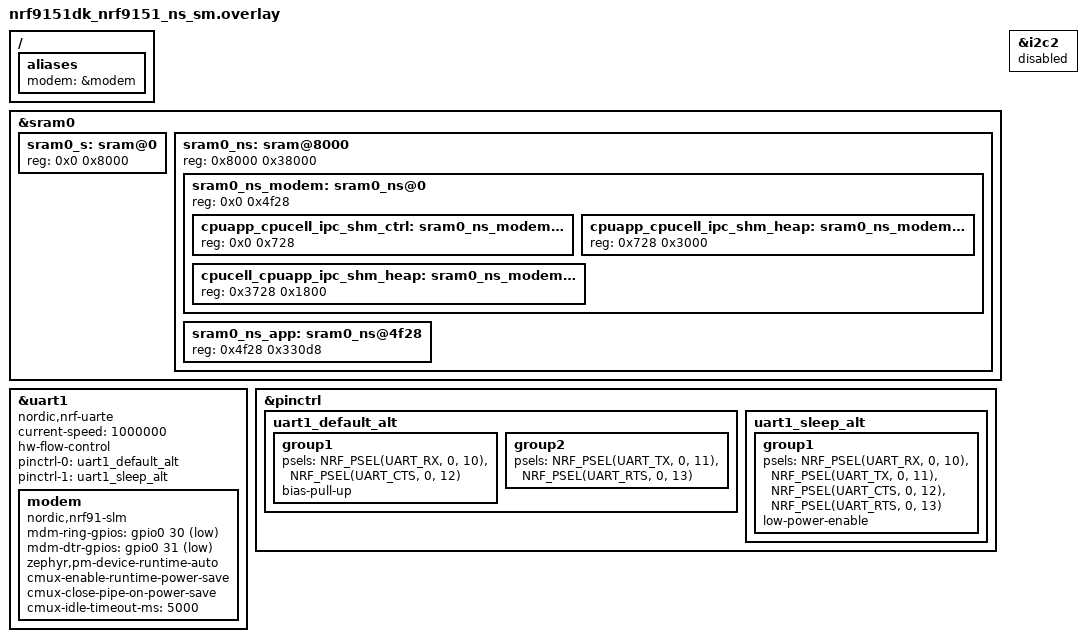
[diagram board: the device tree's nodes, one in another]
/*
 * Copyright (c) 2026 Nordic Semiconductor ASA
 *
 * SPDX-License-Identifier: LicenseRef-Nordic-5-Clause
 */

#include <samples/cellular/nrf91_no_bootloader_partitions.dtsi>

/delete-node/ &sram0_s;
/delete-node/ &sram0_ns;

&sram0 {
	/*
	 * 0x2000_0000  Secure RAM                      (   32 kB)
	 * 0x2000_8000  Non-secure RAM area             (  224 kB)
	 *   0x2000_8000  Modem shared area             ( 20264 B)
	 *     0x2000_8000  control                     (  1832 B)
	 *     0x2000_8728  app -> cell                 (   12 kB)
	 *     0x2000_b728  cell -> app                 (    6 kB)
	 *   0x2000_cf28  Application RAM               (209112 B)
	 */
	sram0_s: sram@0 {
		reg = <0x0 0x8000>;
	};

	sram0_ns: sram@8000 {
		reg = <0x8000 0x38000>;
		#address-cells = <1>;
		#size-cells = <1>;
		ranges = <0x0 0x8000 0x38000>;

		/* Must be in first 128 kB of RAM. */
		sram0_ns_modem: sram0_ns@0 {
			/* Modem (shared) memory */
			reg = <0x0 0x4f28>;
			#address-cells = <1>;
			#size-cells = <1>;
			ranges = <0x0 0x0 0x4f28>;

			cpuapp_cpucell_ipc_shm_ctrl: sram0_ns_modem@0 {
				/* Modem IPC control */
				reg = <0x0 0x728>;
			};

			cpuapp_cpucell_ipc_shm_heap: sram0_ns_modem@728 {
				/* Modem IPC transmit */
				reg = <0x728 0x3000>;
			};

			cpucell_cpuapp_ipc_shm_heap: sram0_ns_modem@3728 {
				/* Modem IPC receive */
				reg = <0x3728 0x1800>;
			};
		};

		sram0_ns_app: sram0_ns@4f28 {
			/* Non-Secure application memory */
			reg = <0x4f28 0x330d8>;
		};
	};
};

/ {
	aliases {
		modem = &modem;
	};
};

&uart1 {
	compatible = "nordic,nrf-uarte";
	current-speed = <1000000>;
	hw-flow-control;
	status = "okay";

	pinctrl-0 = <&uart1_default_alt>;
	pinctrl-1 = <&uart1_sleep_alt>;
	pinctrl-names = "default", "sleep";

	modem: modem {
		compatible = "nordic,nrf91-slm";
		status = "okay";
		mdm-ring-gpios = <&gpio0 30 (GPIO_ACTIVE_LOW | GPIO_PULL_UP)>;
		mdm-dtr-gpios = <&gpio0 31 GPIO_ACTIVE_LOW>;
		zephyr,pm-device-runtime-auto;
		cmux-enable-runtime-power-save;
		cmux-close-pipe-on-power-save;
		cmux-idle-timeout-ms = <5000>;
	};
};

&pinctrl {
	uart1_default_alt: uart1_default_alt {
		group1 {
			psels = <NRF_PSEL(UART_RX, 0, 10)>,
				<NRF_PSEL(UART_CTS, 0, 12)>;
			bias-pull-up;
		};

		group2 {
			psels = <NRF_PSEL(UART_TX, 0, 11)>,
				<NRF_PSEL(UART_RTS, 0, 13)>;
		};
	};

	uart1_sleep_alt: uart1_sleep_alt {
		group1 {
			psels = <NRF_PSEL(UART_RX, 0, 10)>,
				<NRF_PSEL(UART_TX, 0, 11)>,
				<NRF_PSEL(UART_CTS, 0, 12)>,
				<NRF_PSEL(UART_RTS, 0, 13)>;
			low-power-enable;
		};
	};
};

/* Just for sure to disable as these are in 30/31 pins where pwr pin is */
arduino_i2c: &i2c2 {
	status = "disabled";
};
